# ATxmega128A1 register map
Vendor: Atmel; File version: 1.0
CPU: other r0p0, little endian, no MPU, no FPU, 4 interrupt priority bits
Registers are 8-bit, read-write, reset 0x0 unless marked. A register's access mark holds for its fields unless they carry their own. Offsets are from the block's base; [hi:lo] are bit positions; lines under a group give offsets from that group; {n}, {i} and the like mark numbered series; 'fields as' and 'values as' point back to an identical list.

## DFLLRC2M — DFLL
Base 0x00000068
Same registers: DFLLRC32M 0x00000060
0x00 CTRL — Control Register
  [0] ENABLE — DFLL Enable
0x02 CALA — Calibration Register A
  [6:0] CALL — DFLL Calibration bits [6:0]
0x03 CALB — Calibration Register B
  [5:0] CALH — DFLL Calibration bits [12:7]
{0x4+i} COMP{i} (i=0..2) — Oscillator Compare Register {i}

## EBI — External Bus Interface
Base 0x00000440
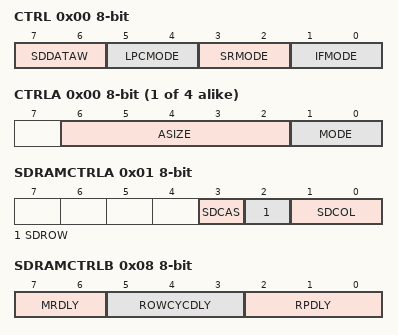
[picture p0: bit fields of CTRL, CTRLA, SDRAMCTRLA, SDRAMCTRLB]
0x00 CTRL — Control
  [7:6] SDDATAW — SDRAM Data Width Setting
    0=4BIT (4-bit data bus); 1=8BIT (8-bit data bus)
  [5:4] LPCMODE — SRAM LPC Mode
    0=ALE1 (Data muxed with addr byte 0); 2=ALE12 (Data muxed with addr byte 0 and 1)
  [3:2] SRMODE — SRAM Mode
    0=ALE1 (Addr byte 0 muxed with 1); 1=ALE2 (Addr byte 0 muxed with 2); 2=ALE12 (Addr byte 0 muxed with 1 and 2); 3=NOALE (No addr muxing)
  [1:0] IFMODE — Interface Mode
    0=DISABLED (EBI Disabled); 1=3PORT (3-port mode); 2=4PORT (4-port mode); 3=2PORT (2-port mode)
0x00 CS{i} group (i=0..3) — EBI Chip Select Module
  0x00 CTRLA — Chip Select Control Register A
    [6:2] ASIZE — Address Size
      0=256B (256 bytes); 1=512B (512 bytes); 2=1KB (1K bytes); 3=2KB (2K bytes); 4=4KB (4K bytes); 5=8KB (8K bytes); 6=16KB (16K bytes); 7=32KB (32K bytes); 8=64KB (64K bytes); 9=128KB (128K bytes); 10=256KB (256K bytes); 11=512KB (512K bytes); 12=1MB (1M bytes); 13=2MB (2M bytes); 14=4MB (4M bytes); 15=8MB (8M bytes); 16=16M (16M bytes)
    [1:0] MODE — Memory Mode
      0=DISABLED (Chip Select Disabled); 1=SRAM (Chip Select in SRAM mode); 2=LPC (Chip Select in SRAM LPC mode); 3=SDRAM (Chip Select in SDRAM mode)
  0x01 CTRLB — Chip Select Control Register B
    [7] SDINITDONE — SDRAM Initialization Done
    [2] SDSREN — SDRAM Self-refresh Enable
    [1:0] SDMODE — SDRAM Mode
      0=NORMAL (Normal mode); 1=LOAD (Load Mode Register command mode)
    [2:0] SRWS — SRAM Wait State Cycles
      0=0CLK (0 cycles); 1=1CLK (1 cycle); {v}={v}CLK ({v} cycles) (v=2..7)
  0x02 BASEADDR 16-bit (reset mask 0xFF) — Base Address
    [15:4] BASEADDR — Chip Select Base Address
0x01 SDRAMCTRLA — SDRAM Control Register A
  [3] SDCAS — SDRAM CAS Latency Setting
  [2] SDROW — SDRAM ROW Bits Setting
  [1:0] SDCOL — SDRAM Column Bits Setting
    {v}={v+8}BIT ({v+8} column bits) (v=0..3)
0x04 REFRESH 16-bit (reset mask 0xFF) — SDRAM Refresh Period
0x06 INITDLY 16-bit (reset mask 0xFF) — SDRAM Initialization Delay
0x08 SDRAMCTRLB — SDRAM Control Register B
  [7:6] MRDLY — SDRAM Mode Register Delay
    0=0CLK (0 cycles); 1=1CLK (1 cycle); 2=2CLK (2 cycles); 3=3CLK (3 cycles)
  [5:3] ROWCYCDLY — SDRAM Row Cycle Delay
    values as CS0.CTRLB.SRWS
  [2:0] RPDLY — SDRAM Row-to-Precharge Delay
    values as CS0.CTRLB.SRWS
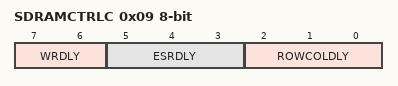
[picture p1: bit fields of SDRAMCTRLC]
0x09 SDRAMCTRLC — SDRAM Control Register C
  [7:6] WRDLY — SDRAM Write Recovery Delay
    values as SDRAMCTRLB.MRDLY
  [5:3] ESRDLY — SDRAM Exit-Self-refresh-to-Active Delay
    values as CS0.CTRLB.SRWS
  [2:0] ROWCOLDLY — SDRAM Row-to-Column Delay
    values as CS0.CTRLB.SRWS

## FUSE — Non Volatile Memory Controller
Base 0x00000000
0x00 FUSEBYTE0 — JTAG User ID
  [7:0] JTAGUSERID
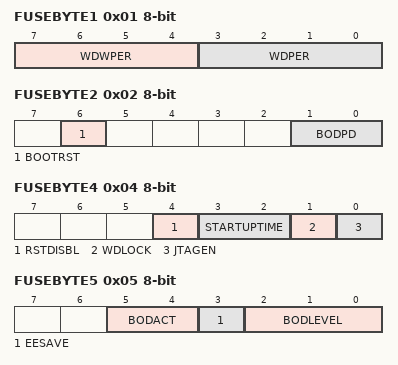
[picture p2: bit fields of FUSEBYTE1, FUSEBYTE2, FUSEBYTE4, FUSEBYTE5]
0x01 FUSEBYTE1 — Watchdog Configuration
  [7:4] WDWPER — Watchdog Window Timeout Period
    0=8CLK (8 cycles (8ms @ 3.3V)); 1=16CLK (16 cycles (16ms @ 3.3V)); 2=32CLK (32 cycles (32ms @ 3.3V)); 3=64CLK (64 cycles (64ms @ 3.3V)); 4=128CLK (128 cycles (0.125s @ 3.3V)); 5=256CLK (256 cycles (0.25s @ 3.3V)); 6=512CLK (512 cycles (0.5s @ 3.3V)); 7=1KCLK (1K cycles (1s @ 3.3V)); 8=2KCLK (2K cycles (2s @ 3.3V)); 9=4KCLK (4K cycles (4s @ 3.3V)); 10=8KCLK (8K cycles (8s @ 3.3V))
  [3:0] WDPER — Watchdog Timeout Period
    values as WDWPER
0x02 FUSEBYTE2 — Reset Configuration
  [6] BOOTRST — Boot Loader Section Reset Vector
    0=BOOTLDR (Boot Loader Reset); 1=APPLICATION (Application Reset)
  [1:0] BODPD — BOD Operation in Power-Down Mode
    1=INSAMPLEDMODE (BOD enabled in sampled mode); 2=CONTINOUSLY (BOD enabled continuously); 3=DISABLED (BOD Disabled)
0x04 FUSEBYTE4 — Start-up Configuration
  [4] RSTDISBL — External Reset Disable
  [3:2] STARTUPTIME
    0=64MS; 1=4MS; 3=0MS
  [1] WDLOCK — Watchdog Timer Lock
  [0] JTAGEN — JTAG Interface Enable
0x05 FUSEBYTE5 — EESAVE and BOD Level
  [5:4] BODACT — BOD Operation in Active Mode
    values as FUSEBYTE2.BODPD
  [3] EESAVE — Preserve EEPROM Through Chip Erase
  [2:0] BODLEVEL — Brownout Detection Voltage Level
    0=3V4 (3.4 V); 1=3V2 (3.2 V); 2=2V9 (2.9 V); 3=2V6 (2.6 V); 4=2V4 (2.4 V); 5=2V1 (2.1 V); 6=1V9 (1.9 V); 7=1V6 (1.6 V)
